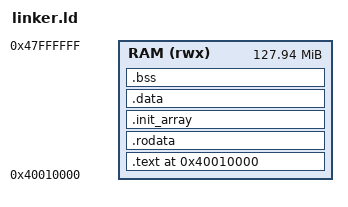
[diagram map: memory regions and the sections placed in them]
/* The entry point defined in your boot.S */
ENTRY(_start)

/* QEMU's ARM 'virt' machine starts its physical RAM at 0x40000000 */
MEMORY
{
    RAM (rwx) : ORIGIN = 0x40010000, LENGTH = 128M - 64K
}

SECTIONS
{
    /* Set the location counter to the start of RAM */
    . = ORIGIN(RAM);

    .text : ALIGN(4096)
    {
        /* 
         * KEEP ensures the linker's garbage collector (--gc-sections) doesn't 
         * discard the entry point. Placing .text.boot first ensures the raw 
         * binary (.bin) starts with executable boot code.
         */
        KEEP(*(.text.boot))
        *(.text .text.*)
    } > RAM

    .rodata : ALIGN(4096)
    {
        *(.rodata .rodata.*)
    } > RAM

    /* 
     * C++ Global Constructors 
     * Even in a freestanding environment, global objects with constructors 
     * compile their initialization routines here. 
     */
    .init_array : ALIGN(4)
    {
        __init_array_start = .;
        KEEP(*(SORT(.init_array.*)))
        KEEP(*(.init_array))
        __init_array_end = .;
    } > RAM

    .data : ALIGN(4096)
    {
        *(.data .data.*)
    } > RAM

    /* 
     * Uninitialized Data (BSS)
     * NOLOAD prevents this section from occupying space in the raw .bin file.
     */
    .bss (NOLOAD) : ALIGN(4096)
    {
        __bss_start = .;
        *(.bss .bss.*)
        *(COMMON)
        __bss_end = .;
    } > RAM

    /* 
     * Boot Stack Provisioning
     * Allocate 64 KB for the initial Hyp-mode boot stack.
     * Aligned to 8 bytes per the ARM Architecture Procedure Call Standard (AAPCS).
     */
    . = ALIGN(8);
    . = . + 0x10000; /* 64 KB */
    . = ALIGN(4096);
    __stack_top = .;
    
    /* Discard host-OS specific sections generated by GCC */
    /DISCARD/ :
    {
        *(.note.GNU-stack)
        *(.gnu_debuglink)
        *(.interp)
        *(.comment)
    }
}
